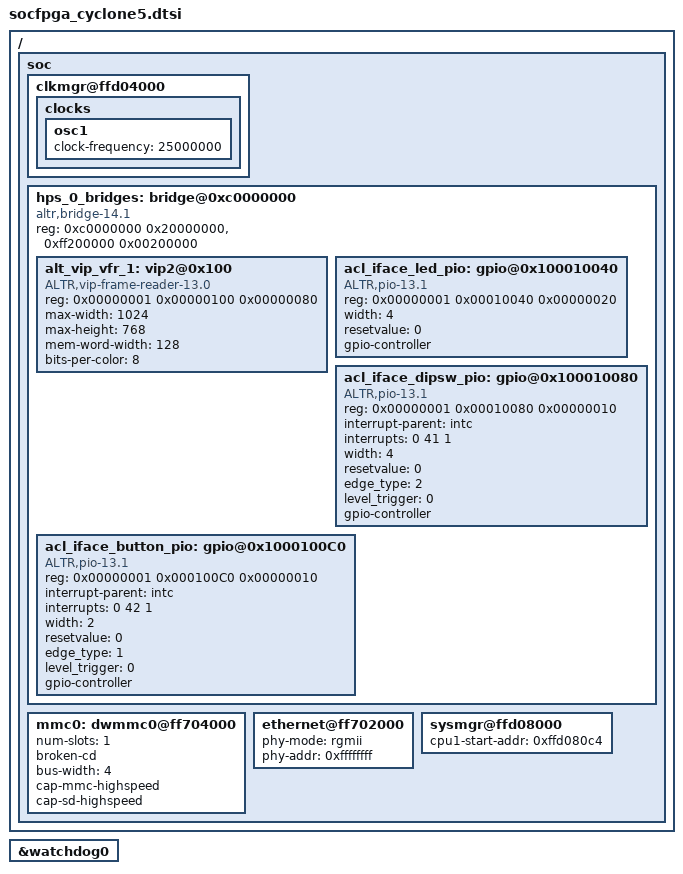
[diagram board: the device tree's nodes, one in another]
/*
 * Copyright Altera Corporation (C) 2012,2014. All rights reserved.
 *
 * This program is free software; you can redistribute it and/or modify
 * it under the terms and conditions of the GNU General Public License,
 * version 2, as published by the Free Software Foundation.
 *
 * This program is distributed in the hope it will be useful, but WITHOUT
 * ANY WARRANTY; without even the implied warranty of MERCHANTABILITY or
 * FITNESS FOR A PARTICULAR PURPOSE.  See the GNU General Public License for
 * more details.
 *
 * You should have received a copy of the GNU General Public License along with
 * this program.  If not, see <http://www.gnu.org/licenses/>.
 */

/dts-v1/;
/* First 4KB has trampoline code for secondary cores. */
/memreserve/ 0x00000000 0x0001000;
#include "socfpga.dtsi"

/ {
	soc {
		clkmgr@ffd04000 {
			clocks {
				osc1 {
					clock-frequency = <25000000>;
				};
			};
		};

		hps_0_bridges: bridge@0xc0000000 {
			compatible = "altr,bridge-14.1", "simple-bus";
			reg = <0xc0000000 0x20000000>,
				<0xff200000 0x00200000>;
			reg-names = "axi_h2f", "axi_h2f_lw";
			#address-cells = <2>;
			#size-cells = <1>;
			ranges = <0x00000000 0x00000000 0xc0000000 0x00010000>,
				<0x00000001 0x00000100 0xFF200100 0x00000080>,
				<0x00000001 0x00010040 0xFF210040 0x00000020>,
				<0x00000001 0x00010080 0xFF210080 0x00000010>,
				<0x00000001 0x000100C0 0xFF2100C0 0x00000010>;

			alt_vip_vfr_1: vip2@0x100 {	
				compatible = "ALTR,vip-frame-reader-13.0", "ALTR,vip-frame-reader-9.1";
				reg = <0x00000001 0x00000100 0x00000080 >;
				max-width = < 1024 >;	
				max-height = < 768 >;	
				mem-word-width = < 128 >;
				bits-per-color = < 8 >;				
				}; //end vip@0x40100 (alt_vip_vfr_0)

			acl_iface_led_pio: gpio@0x100010040 {
				compatible = "ALTR,pio-13.1", "ALTR,pio-1.0", "altr,pio-1.0";
				reg = <0x00000001 0x00010040 0x00000020 >;
				width = < 4 >;	/* embeddedsw.dts.params.width type NUMBER */
				resetvalue = < 0 >;	/* embeddedsw.dts.params.resetvalue type NUMBER */
				#gpio-cells = < 2 >;
				gpio-controller;
				}; //end gpio@0x100010040 (acl_iface_led_pio)
			acl_iface_dipsw_pio: gpio@0x100010080 {
				compatible = "ALTR,pio-13.1", "ALTR,pio-1.0", "altr,pio-1.0";
				reg = <0x00000001 0x00010080 0x00000010 >;
				interrupt-parent = < &intc >;
				interrupts = < 0 41 1 >;
				width = < 4 >;	/* embeddedsw.dts.params.width type NUMBER */
				resetvalue = < 0 >;	/* embeddedsw.dts.params.resetvalue type NUMBER */
				edge_type = < 2 >;	/* embeddedsw.dts.params.edge_type type NUMBER */
				level_trigger = < 0 >;	/* embeddedsw.dts.params.level_trigger type NUMBER */
				#gpio-cells = < 2 >;
				gpio-controller;
				}; //end gpio@0x100010080 (acl_iface_dipsw_pio)

			acl_iface_button_pio: gpio@0x1000100C0 {
				compatible = "ALTR,pio-13.1", "ALTR,pio-1.0", "altr,pio-1.0";
				reg = <0x00000001 0x000100C0 0x00000010 >;
				interrupt-parent = < &intc >;
				interrupts = < 0 42 1 >;
				width = < 2 >;	/* embeddedsw.dts.params.width type NUMBER */
				resetvalue = < 0 >;	/* embeddedsw.dts.params.resetvalue type NUMBER */
				edge_type = < 1 >;	/* embeddedsw.dts.params.edge_type type NUMBER */
				level_trigger = < 0 >;	/* embeddedsw.dts.params.level_trigger type NUMBER */
				#gpio-cells = < 2 >;
				gpio-controller;
				}; //end gpio@0x1000100C0 (acl_iface_button_pio)

		}; //end bridge@0xc0000000 (hps_0_bridges)

		mmc0: dwmmc0@ff704000 {
			num-slots = <1>;
			broken-cd;
			bus-width = <4>;
			cap-mmc-highspeed;
			cap-sd-highspeed;
		};

		ethernet@ff702000 {
			phy-mode = "rgmii";
			phy-addr = <0xffffffff>; /* probe for phy addr */
			status = "okay";
		};

		sysmgr@ffd08000 {
			cpu1-start-addr = <0xffd080c4>;
		};
	};
};

&watchdog0 {
	status = "okay";
};
